# nrf5340_application register map
Vendor: Nordic Semiconductor; Series: nrf53; File version: 1
CPU: CM33 r0p4, little endian, MPU, FPU, 3 interrupt priority bits, 69 interrupts
Registers are 32-bit, read-write, reset 0x0 unless marked. A register's access mark holds for its fields unless they carry their own. Offsets are from the block's base; [hi:lo] are bit positions; lines under a group give offsets from that group; {n}, {i} and the like mark numbered series; 'fields as' and 'values as' point back to an identical list.

## QSPI_NS — External flash interface 0
Base 0x4002B000
Same registers: QSPI_S 0x5002B000
0x00 TASKS_ACTIVATE wo — Activate QSPI interface
  [0] TASKS_ACTIVATE
    1=Trigger task
0x04 TASKS_READSTART wo — Start transfer from external flash memory to internal RAM
  [0] TASKS_READSTART
    1=Trigger task
0x08 TASKS_WRITESTART wo — Start transfer from internal RAM to external flash memory
  [0] TASKS_WRITESTART
    1=Trigger task
0x0C TASKS_ERASESTART wo — Start external flash memory erase operation
  [0] TASKS_ERASESTART
    1=Trigger task
0x10 TASKS_DEACTIVATE wo — Deactivate QSPI interface
  [0] TASKS_DEACTIVATE
    1=Trigger task
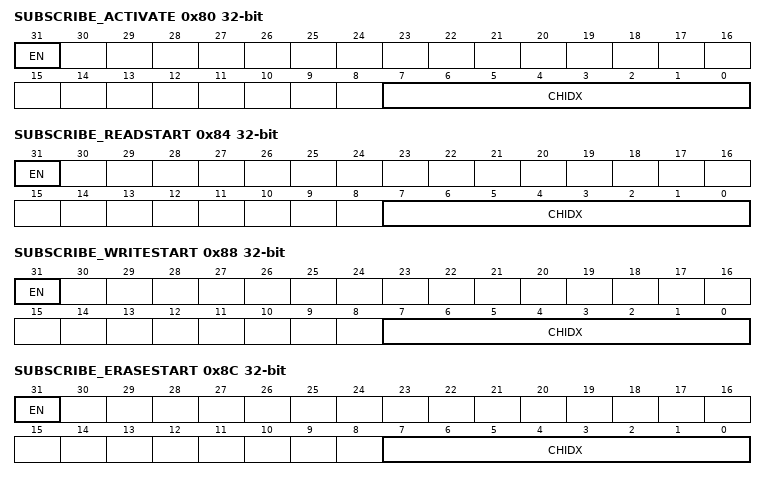
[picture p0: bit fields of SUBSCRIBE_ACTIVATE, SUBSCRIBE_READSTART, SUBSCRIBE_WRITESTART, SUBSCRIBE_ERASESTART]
0x80 SUBSCRIBE_ACTIVATE — Subscribe configuration for task ACTIVATE
  [31] EN
    0=Disabled (Disable subscription); 1=Enabled (Enable subscription)
  [7:0] CHIDX — DPPI channel that task ACTIVATE will subscribe to
0x84 SUBSCRIBE_READSTART — Subscribe configuration for task READSTART
  [31] EN
    values as SUBSCRIBE_ACTIVATE.EN
  [7:0] CHIDX — DPPI channel that task READSTART will subscribe to
0x88 SUBSCRIBE_WRITESTART — Subscribe configuration for task WRITESTART
  [31] EN
    values as SUBSCRIBE_ACTIVATE.EN
  [7:0] CHIDX — DPPI channel that task WRITESTART will subscribe to
0x8C SUBSCRIBE_ERASESTART — Subscribe configuration for task ERASESTART
  [31] EN
    values as SUBSCRIBE_ACTIVATE.EN
  [7:0] CHIDX — DPPI channel that task ERASESTART will subscribe to
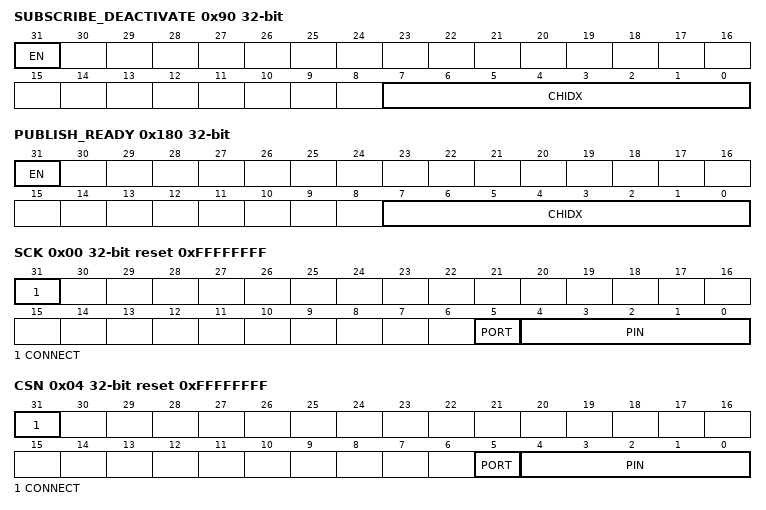
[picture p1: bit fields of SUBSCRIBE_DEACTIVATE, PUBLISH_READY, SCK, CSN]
0x90 SUBSCRIBE_DEACTIVATE — Subscribe configuration for task DEACTIVATE
  [31] EN
    values as SUBSCRIBE_ACTIVATE.EN
  [7:0] CHIDX — DPPI channel that task DEACTIVATE will subscribe to
0x100 EVENTS_READY — QSPI peripheral is ready. This event will be generated as a response to all QSPI tasks except DEACTIVATE.
  [0] EVENTS_READY
    0=NotGenerated (Event not generated); 1=Generated (Event generated)
0x180 PUBLISH_READY — Publish configuration for event READY
  [31] EN
    0=Disabled (Disable publishing); 1=Enabled (Enable publishing)
  [7:0] CHIDX — DPPI channel that event READY will publish to.
0x300 INTEN — Enable or disable interrupt
  [0] READY — Enable or disable interrupt for event READY
    0=Disabled; 1=Enabled
0x304 INTENSET — Enable interrupt
  [0] READY — Write '1' to enable interrupt for event READY
    on read: 0=Disabled (Read: Disabled); 1=Enabled (Read: Enabled) | on write: 1=Set (Enable)
0x308 INTENCLR — Disable interrupt
  [0] READY — Write '1' to disable interrupt for event READY
    on read: 0=Disabled (Read: Disabled); 1=Enabled (Read: Enabled) | on write: 1=Clear (Disable)
0x500 ENABLE — Enable QSPI peripheral and acquire the pins selected in PSELn registers
  [0] ENABLE — Enable or disable QSPI
    0=Disabled (Disable QSPI); 1=Enabled (Enable QSPI)
0x504 READ group — Unspecified
  0x00 SRC — Flash memory source address
    [31:0] SRC — Word-aligned flash memory source address.
  0x04 DST — RAM destination address
    [31:0] DST — Word-aligned RAM destination address.
  0x08 CNT — Read transfer length
    [20:0] CNT — Read transfer length in number of bytes. The length must be a multiple of 4 bytes.
0x510 WRITE group — Unspecified
  0x00 DST — Flash destination address
    [31:0] DST — Word-aligned flash destination address.
  0x04 SRC — RAM source address
    [31:0] SRC — Word-aligned RAM source address.
  0x08 CNT — Write transfer length
    [20:0] CNT — Write transfer length in number of bytes. The length must be a multiple of 4 bytes.
0x51C ERASE group — Unspecified
  0x00 PTR — Start address of flash block to be erased
    [31:0] PTR — Word-aligned start address of block to be erased.
  0x04 LEN — Size of block to be erased.
    [1:0] LEN
      0=4KB (Erase 4 kB block (flash command 0x20)); 1=64KB (Erase 64 kB block (flash command 0xD8)); 2=All (Erase all (flash command 0xC7))
0x524 PSEL group — Unspecified
  0x00 SCK reset 0xFFFFFFFF — Pin select for serial clock SCK
    [31] CONNECT — Connection
      1=Disconnected; 0=Connected
    [5] PORT — Port number
    [4:0] PIN — Pin number
  0x04 CSN reset 0xFFFFFFFF — Pin select for chip select signal CSN.
    fields as PSEL.SCK
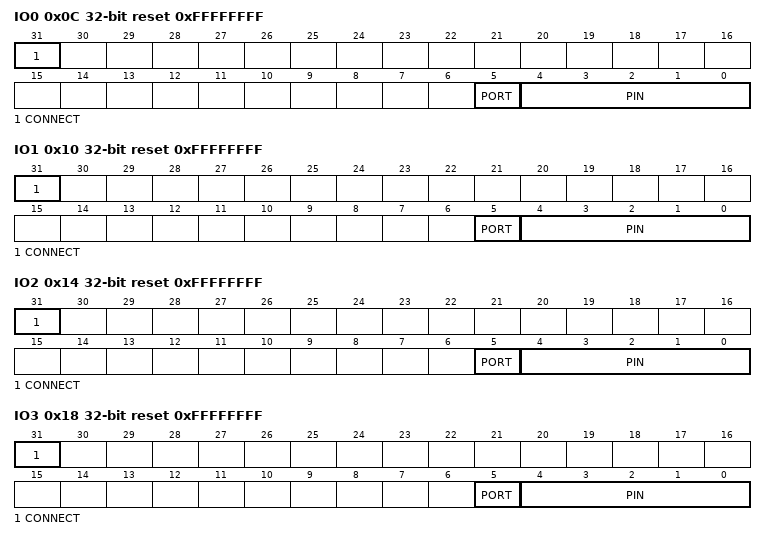
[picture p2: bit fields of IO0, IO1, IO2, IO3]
  0x0C IO0 reset 0xFFFFFFFF — Pin select for serial data MOSI/IO0.
    fields as PSEL.SCK
  0x10 IO1 reset 0xFFFFFFFF — Pin select for serial data MISO/IO1.
    fields as PSEL.SCK
  0x14 IO2 reset 0xFFFFFFFF — Pin select for serial data WP/IO2.
    fields as PSEL.SCK
  0x18 IO3 reset 0xFFFFFFFF — Pin select for serial data HOLD/IO3.
    fields as PSEL.SCK
0x540 XIPOFFSET — Address offset into the external memory for Execute in Place operation.
  [31:0] XIPOFFSET — Address offset into the external memory for Execute in Place operation. Value must be a multiple of 4.
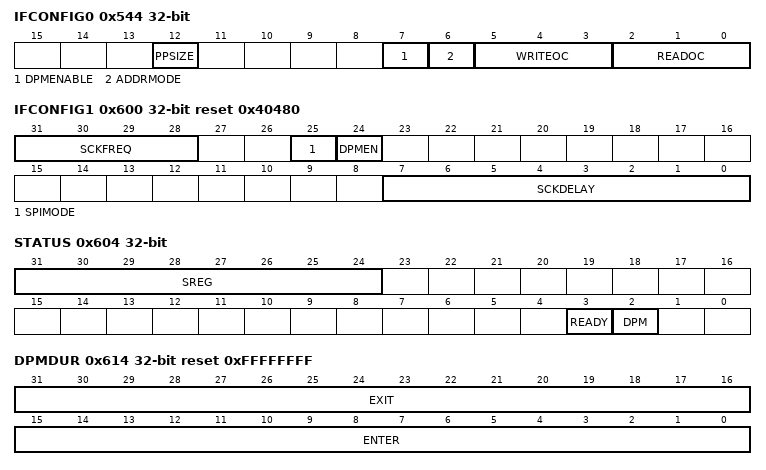
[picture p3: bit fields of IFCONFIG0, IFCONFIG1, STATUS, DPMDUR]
0x544 IFCONFIG0 — Interface configuration.
  [12] PPSIZE — Page size for commands PP, PP2O, PP4O and PP4IO.
    0=256Bytes; 1=512Bytes
  [7] DPMENABLE — Enable deep power-down mode (DPM) feature.
    0=Disable DPM feature; 1=Enable DPM feature
  [6] ADDRMODE — Addressing mode.
    0=24BIT (24-bit addressing.); 1=32BIT (32-bit addressing.)
  [5:3] WRITEOC — Configure number of data lines and opcode used for writing.
    0=PP (Single data line SPI. PP (opcode 0x02).); 1=PP2O (Dual data line SPI. PP2O (opcode 0xA2).); 2=PP4O (Quad data line SPI. PP4O (opcode 0x32).); 3=PP4IO (Quad data line SPI. PP4IO (opcode 0x38).)
  [2:0] READOC — Configure number of data lines and opcode used for reading.
    0=FASTREAD (Single data line SPI. FAST_READ (opcode 0x0B).); 1=READ2O (Dual data line SPI. READ2O (opcode 0x3B).); 2=READ2IO (Dual data line SPI. READ2IO (opcode 0xBB).); 3=READ4O (Quad data line SPI. READ4O (opcode 0x6B).); 4=READ4IO (Quad data line SPI. READ4IO (opcode 0xEB).)
0x54C XIPEN reset 0x1 — Enable Execute in Place operation.
  [0] XIPEN — Enable XIP AHB Slave interface and access to XIP memory range
    0=Disable XIP interface; 1=Enable XIP interface
0x560 XIP_ENC group — Unspecified
  {0x0+4j} KEY{j} wo (j=0..3) — Bits {32j+31}:{32j} of XIP AES KEY
  {0x10+4j} NONCE{j} wo (j=0..2) — Bits {32j+31}:{32j} of XIP NONCE
  0x1C ENABLE — Enable stream cipher for XIP
    [0] ENABLE — Enable or disable stream cipher for XIP
      0=Disabled (Disable stream cipher for QSPI XIP); 1=Enabled (Enable stream cipher for QSPI XIP)
0x580 DMA_ENC group — Unspecified
  {0x0+4j} KEY{j} wo (j=0..3) — Bits {32j+31}:{32j} of DMA AES KEY
  {0x10+4j} NONCE{j} wo (j=0..2) — Bits {32j+31}:{32j} of DMA NONCE
  0x1C ENABLE — Enable stream cipher for EasyDMA
    [0] ENABLE — Enable or disable stream cipher for EasyDMA
      0=Disabled (Disable stream cipher for QSPI EasyDMA); 1=Enabled (Enable stream cipher for QSPI EasyDMA)
0x600 IFCONFIG1 reset 0x40480 — Interface configuration.
  [31:28] SCKFREQ — SCK frequency is derived from PCLK192M with SCK frequency = PCLK192M / (2*(SCKFREQ + 1)).
  [25] SPIMODE — Select SPI mode.
    0=MODE0 (Mode 0: Data are captured on the clock rising edge and data is output on a falling edge. Base level of clock is 0 (CPOL=0, CPHA=0).); 1=MODE3 (Mode 3: Data are captured on the clock rising edge and data is output on a falling edge. Base level of clock is 1 (CPOL=1, CPHA=1).)
  [24] DPMEN — Enter/exit deep power-down mode (DPM) for external flash memory.
    0=Exit DPM; 1=Enter DPM
  [7:0] SCKDELAY — Minimum amount of time that the CSN pin must stay high before it can go low again. Value is specified in number of 32 MHz periods (31.25 ns).
0x604 STATUS ro
  [31:24] SREG — Value of external flash device Status Register. When the external flash has two bytes status register this field includes the value of the low byte.
  [3] READY — Ready status.
    1=READY (QSPI peripheral is ready. It is allowed to trigger new tasks, writing custom instructions or enter/exit DPM.); 0=BUSY (QSPI peripheral is busy. It is not allowed to trigger any new tasks, writing custom instructions or enter/exit DPM.)
  [2] DPM — Deep power-down mode (DPM) status of external flash.
    0=Disabled (External flash is not in DPM.); 1=Enabled (External flash is in DPM.)
0x614 DPMDUR reset 0xFFFFFFFF — Set the duration required to enter/exit deep power-down mode (DPM).
  [31:16] EXIT — Duration needed by external flash to exit DPM. Duration is given as EXIT * 256 * 31.25 ns.
  [15:0] ENTER — Duration needed by external flash to enter DPM. Duration is given as ENTER * 256 * 31.25 ns
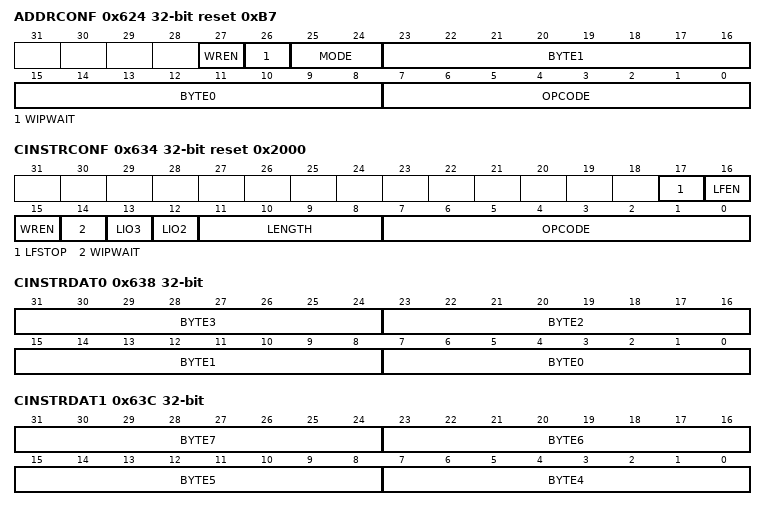
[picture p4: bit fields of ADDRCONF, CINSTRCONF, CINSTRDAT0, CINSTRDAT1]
0x624 ADDRCONF reset 0xB7 — Extended address configuration.
  [27] WREN — Send WREN (write enable opcode 0x06) before instruction.
    0=Disable (Do not send WREN.); 1=Enable (Send WREN.)
  [26] WIPWAIT — Wait for write complete before sending command.
    0=Disable (No wait.); 1=Enable (Wait.)
  [25:24] MODE — Extended addressing mode.
    0=NoInstr (Do not send any instruction.); 1=Opcode (Send opcode.); 2=OpByte0 (Send opcode, BYTE0.); 3=All (Send opcode, BYTE0, BYTE1.)
  [23:16] BYTE1 — Byte 1 following byte 0.
  [15:8] BYTE0 — Byte 0 following opcode.
  [7:0] OPCODE — Opcode that enters the 32-bit addressing mode.
0x634 CINSTRCONF reset 0x2000 — Custom instruction configuration register.
  [17] LFSTOP — Stop (finalize) long frame transaction
    1=Stop
  [16] LFEN — Enable Long frame mode. When enabled, a custom instruction transaction has to be ended by writing the LFSTOP field.
    0=Disable (Long frame mode disabled); 1=Enable (Long frame mode enabled)
  [15] WREN — Send WREN (write enable opcode 0x06) before instruction.
    0=Disable (Do not send WREN.); 1=Enable (Send WREN.)
  [14] WIPWAIT — Wait for write complete before sending command.
    0=Disable (No wait.); 1=Enable (Wait.)
  [13] LIO3 — Level of the IO3 pin (if connected) during transmission of custom instruction.
  [12] LIO2 — Level of the IO2 pin (if connected) during transmission of custom instruction.
  [11:8] LENGTH — Length of custom instruction in number of bytes.
    1=1B (Send opcode only.); 2=2B (Send opcode, CINSTRDAT0.BYTE0.); 3=3B (Send opcode, CINSTRDAT0.BYTE0 -> CINSTRDAT0.BYTE1.); 4=4B (Send opcode, CINSTRDAT0.BYTE0 -> CINSTRDAT0.BYTE2.); 5=5B (Send opcode, CINSTRDAT0.BYTE0 -> CINSTRDAT0.BYTE3.); {v}={v}B (Send opcode, CINSTRDAT0.BYTE0 -> CINSTRDAT1.BYTE{v-2}.) (v=6..9)
  [7:0] OPCODE — Opcode of Custom instruction.
0x638 CINSTRDAT0 — Custom instruction data register 0.
  [8n+7:8n] BYTE{n} (n=0..3) — Data byte {n}
0x63C CINSTRDAT1 — Custom instruction data register 1.
  [8n-25:8n-32] BYTE{n} (n=4..7) — Data byte {n}
0x640 IFTIMING reset 0x200 — SPI interface timing.
  [10:8] RXDELAY — Timing related to sampling of the input serial data. The value of RXDELAY specifies the number of prescaled 192 MHz cycles delay from the the rising edge of the SPI Clock (SCK) until the input serial data is sampled. For example, if RXDELAY is set to 0, the input serial data is sampled on the rising edge of SCK.

## Notices in the file
Copyright (c) 2010 - 2024, Nordic Semiconductor ASA All rights reserved.
SPDX-License-Identifier: BSD-3-Clause
Redistribution and use in source and binary forms, with or without
modification, are permitted provided that the following conditions are met:
1. Redistributions of source code must retain the above copyright notice, this
list of conditions and the following disclaimer.
2. Redistributions in binary form must reproduce the above copyright
notice, this list of conditions and the following disclaimer in the
documentation and/or other materials provided with the distribution.
3. Neither the name of Nordic Semiconductor ASA nor the names of its
contributors may be used to endorse or promote products derived from this
software without specific prior written permission.
THIS SOFTWARE IS PROVIDED BY THE COPYRIGHT HOLDERS AND CONTRIBUTORS "AS IS"
AND ANY EXPRESS OR IMPLIED WARRANTIES, INCLUDING, BUT NOT LIMITED TO, THE
IMPLIED WARRANTIES OF MERCHANTABILITY, AND FITNESS FOR A PARTICULAR PURPOSE
ARE DISCLAIMED. IN NO EVENT SHALL NORDIC SEMICONDUCTOR ASA OR CONTRIBUTORS BE
LIABLE FOR ANY DIRECT, INDIRECT, INCIDENTAL, SPECIAL, EXEMPLARY, OR
CONSEQUENTIAL DAMAGES (INCLUDING, BUT NOT LIMITED TO, PROCUREMENT OF
SUBSTITUTE GOODS OR SERVICES; LOSS OF USE, DATA, OR PROFITS; OR BUSINESS
INTERRUPTION) HOWEVER CAUSED AND ON ANY THEORY OF LIABILITY, WHETHER IN
CONTRACT, STRICT LIABILITY, OR TORT (INCLUDING NEGLIGENCE OR OTHERWISE)
ARISING IN ANY WAY OUT OF THE USE OF THIS SOFTWARE, EVEN IF ADVISED OF THE
POSSIBILITY OF SUCH DAMAGE.
